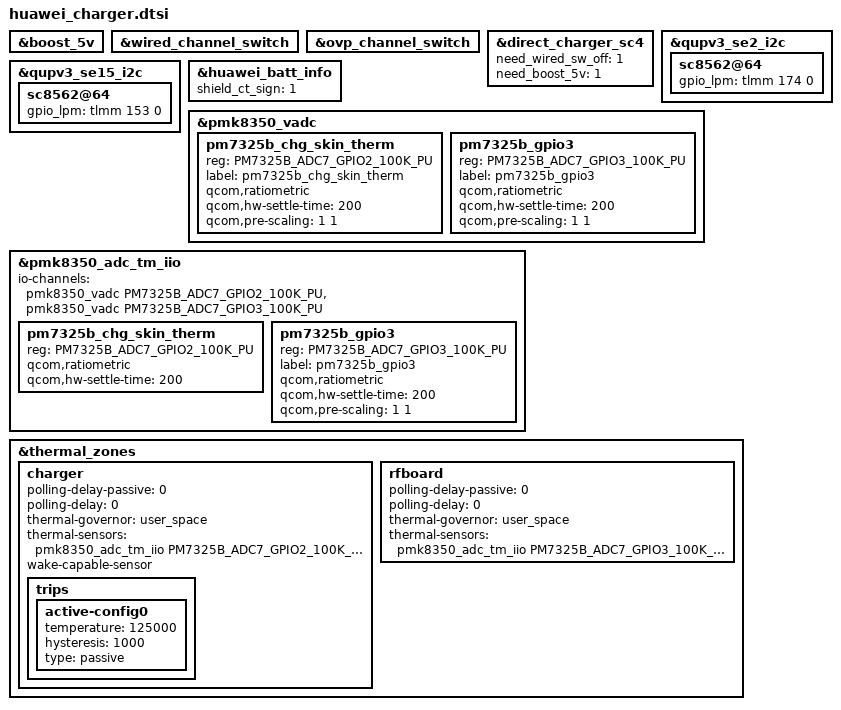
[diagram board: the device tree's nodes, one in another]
#include <dt-bindings/iio/qcom,spmi-adc7-pm7325b.h>
&boost_5v {
	status = "ok";
};

&wired_channel_switch {
	status = "ok";
};

&ovp_channel_switch {
	status = "ok";
};

&direct_charger_sc4 {
	need_wired_sw_off = <1>;
	need_boost_5v = <1>;
};

&qupv3_se2_i2c {
	sc8562@64{
		gpio_lpm = <&tlmm 174 0>;
		status = "ok";
	};
};

&qupv3_se15_i2c {
	sc8562@64{
		gpio_lpm = <&tlmm 153 0>;
		status = "ok";
	};
};

&huawei_batt_info {
    shield_ct_sign = <1>;
};

&pmk8350_vadc {

	pm7325b_chg_skin_therm {
		reg = <PM7325B_ADC7_GPIO2_100K_PU>;
		label = "pm7325b_chg_skin_therm";
		qcom,ratiometric;
		qcom,hw-settle-time = <200>;
		qcom,pre-scaling = <1 1>;
	};

	pm7325b_gpio3 {
		reg = <PM7325B_ADC7_GPIO3_100K_PU>;
		label = "pm7325b_gpio3";
		qcom,ratiometric;
		qcom,hw-settle-time = <200>;
		qcom,pre-scaling = <1 1>;
    };

};

&pmk8350_adc_tm_iio {
	io-channels =<&pmk8350_vadc PM7325B_ADC7_GPIO2_100K_PU>,
                     <&pmk8350_vadc PM7325B_ADC7_GPIO3_100K_PU>;

	pm7325b_chg_skin_therm {
		reg = <PM7325B_ADC7_GPIO2_100K_PU>;
		qcom,ratiometric;
		qcom,hw-settle-time = <200>;
	};

	pm7325b_gpio3 {
		reg = <PM7325B_ADC7_GPIO3_100K_PU>;
		label = "pm7325b_gpio3";
		qcom,ratiometric;
		qcom,hw-settle-time = <200>;
		qcom,pre-scaling = <1 1>;
    };
};

&thermal_zones {
	charger {
		polling-delay-passive = <0>;
		polling-delay = <0>;
		thermal-governor = "user_space";
		thermal-sensors = <&pmk8350_adc_tm_iio PM7325B_ADC7_GPIO2_100K_PU>;
		wake-capable-sensor;
		trips {
			active-config0 {
				temperature = <125000>;
				hysteresis = <1000>;
				type = "passive";
			};
		};
	};
	rfboard {
		polling-delay-passive = <0>;
		polling-delay = <0>;
		thermal-governor = "user_space";
		thermal-sensors = <&pmk8350_adc_tm_iio PM7325B_ADC7_GPIO3_100K_PU>;
	};
};
